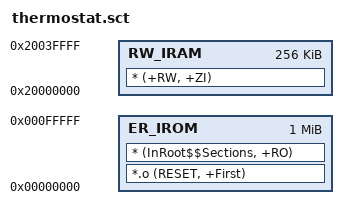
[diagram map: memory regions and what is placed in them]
;******************************************************************************
;
; thermostat.sct - Linker configuration file for thermostat.
;
;******************************************************************************

LR_IROM 0x00000000 0x00100000
{
    ;
    ; Specify the Execution Address of the code and the size.
    ;
    ER_IROM 0x00000000 0x00100000
    {
        *.o (RESET, +First)
        * (InRoot$$Sections, +RO)
    }

    ;
    ; Specify the Execution Address of the data area.
    ;
    RW_IRAM 0x20000000 0x00040000
    {
        ;
        ; Uncomment the following line in order to use IntRegister().
        ;
        ;* (vtable, +First)
        * (+RW, +ZI)
    }
}
